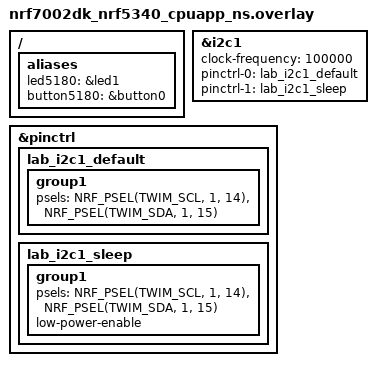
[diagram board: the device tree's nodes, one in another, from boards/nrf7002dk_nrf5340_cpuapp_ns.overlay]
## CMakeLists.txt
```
# SPDX-License-Identifier: Apache-2.0

cmake_minimum_required(VERSION 3.20.0)
find_package(Zephyr REQUIRED HINTS $ENV{ZEPHYR_BASE})
project(lab0_sum)

target_sources(app PRIVATE src/main.c)

if(CONFIG_SUM_PRINT)
    target_sources(app PRIVATE sum_printk/sum_printk.c)
    target_include_directories(app PRIVATE sum_printk)
elseif(CONFIG_SUM_LOG)
    target_sources(app PRIVATE sum_log/sum_log.c)
    target_include_directories(app PRIVATE sum_log)
endif()
```

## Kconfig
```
mainmenu "Lab 0 application"

source "Kconfig.zephyr"

choice SUM_IMPLEMENTATION
    prompt "Sum implementation"
    default SUM_PRINT

config SUM_PRINT
    bool "Use printk"

config SUM_LOG
    bool "Use Logger"
    depends on LOG

endchoice
```

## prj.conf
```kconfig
CONFIG_GPIO=y
CONFIG_SERIAL=y
CONFIG_CONSOLE=y
CONFIG_UART_CONSOLE=y
CONFIG_PRINTK=y

CONFIG_LOG=y
CONFIG_LOG_BACKEND_UART=y
CONFIG_LOG_DEFAULT_LEVEL=3

CONFIG_SUM_LOG=y

CONFIG_I2C=y
CONFIG_TFM_SECURE_UART=n
CONFIG_TFM_LOG_LEVEL_SILENCE=y

CONFIG_SENSOR=y
CONFIG_CBPRINTF_FP_SUPPORT=y
```

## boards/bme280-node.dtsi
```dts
bme5180: bme280@77 {
    compatible = "i2c-device";
    status = "okay";
    reg = <0x77>;
};
```

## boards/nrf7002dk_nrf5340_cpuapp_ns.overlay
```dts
#include <zephyr/dt-bindings/pinctrl/nrf-pinctrl.h>

/ {
    aliases {
        led5180 = &led1;
        button5180 = &button0;
    };
};

&i2c1 {
    status = "okay";
    clock-frequency = <100000>;

    pinctrl-0 = <&lab_i2c1_default>;
    pinctrl-1 = <&lab_i2c1_sleep>;
    pinctrl-names = "default", "sleep";

    #include "bme280-node.dtsi"
};

&pinctrl {
    lab_i2c1_default: lab_i2c1_default {
        group1 {
            psels = <NRF_PSEL(TWIM_SCL, 1, 14)>,
                    <NRF_PSEL(TWIM_SDA, 1, 15)>;
        };
    };

    lab_i2c1_sleep: lab_i2c1_sleep {
        group1 {
            psels = <NRF_PSEL(TWIM_SCL, 1, 14)>,
                    <NRF_PSEL(TWIM_SDA, 1, 15)>;
            low-power-enable;
        };
    };
};
```

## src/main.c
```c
#include <zephyr/kernel.h>
#include <zephyr/drivers/i2c.h>
#include <zephyr/sys/byteorder.h>
#include <zephyr/sys/printk.h>
#include <errno.h>
#include "bme_temperature.h"

static const struct i2c_dt_spec bme =
    I2C_DT_SPEC_GET(DT_NODELABEL(bme5180));

static uint16_t dig_T1;
static int16_t dig_T2;
static int16_t dig_T3;

static int wait_ready(void)
{
    for (int i = 0; i < 50; i++) {
        uint8_t status;
        int ret = i2c_reg_read_byte_dt(&bme, 0xF3, &status);

        if (ret < 0) {
            return ret;
        }

        if ((status & 0x09) == 0) {
            return 0;
        }

        k_msleep(2);
    }

    return -ETIMEDOUT;
}

static double compensate_temperature(int32_t raw)
{
    return bme_compensate_temperature(raw, dig_T1, dig_T2, dig_T3);
}

int main(void)
{
    int ret;
    uint8_t chip_id;
    uint8_t calibration[6];

    if (!i2c_is_ready_dt(&bme)) {
        printk("I2C controller not ready\n");
        return 0;
    }

    k_msleep(10);

    ret = i2c_reg_read_byte_dt(&bme, 0xD0, &chip_id);
    if (ret < 0) {
        printk("Chip ID read failed: %d\n", ret);
        return 0;
    }

    if (chip_id != 0x60) {
        printk("Unexpected chip ID: 0x%02x\n",
               (unsigned int)chip_id);
        return 0;
    }

    printk("BME280 connected!\n");

    ret = i2c_reg_write_byte_dt(&bme, 0xE0, 0xB6);
    if (ret < 0) {
        printk("Sensor reset failed: %d\n", ret);
        return 0;
    }

    k_msleep(10);

    ret = wait_ready();
    if (ret < 0) {
        printk("Sensor startup failed: %d\n", ret);
        return 0;
    }

    ret = i2c_burst_read_dt(&bme, 0x88,
                           calibration, sizeof(calibration));
    if (ret < 0) {
        printk("Calibration read failed: %d\n", ret);
        return 0;
    }

    dig_T1 = sys_get_le16(&calibration[0]);
    dig_T2 = (int16_t)sys_get_le16(&calibration[2]);
    dig_T3 = (int16_t)sys_get_le16(&calibration[4]);

    printk("Calibration: T1=%u, T2=%d, T3=%d\n",
           (unsigned int)dig_T1, (int)dig_T2, (int)dig_T3);

    while (1) {
        ret = i2c_reg_write_byte_dt(&bme, 0xF4, 0x21);
        if (ret < 0) {
            printk("Measurement start failed: %d\n", ret);
            k_msleep(2000);
            continue;
        }

        k_msleep(10);

        ret = wait_ready();
        if (ret < 0) {
            printk("Measurement wait failed: %d\n", ret);
            k_msleep(2000);
            continue;
        }

        uint8_t data[3];

        ret = i2c_burst_read_dt(&bme, 0xFA, data, sizeof(data));
        if (ret < 0) {
            printk("Temperature read failed: %d\n", ret);
            k_msleep(2000);
            continue;
        }

        int32_t raw = bme_decode_raw(data);
        
        if (raw == 0x80000) {
            printk("Temperature sample unavailable\n");
            k_msleep(2000);
            continue;
        }

        double temperature = compensate_temperature(raw);

        printk("Raw: %ld | Temperature: %.2f C\n",
               (long)raw, temperature);

        k_msleep(2000);
    }

    return 0;
}
```

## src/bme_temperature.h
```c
#ifndef BME_TEMPERATURE_H
#define BME_TEMPERATURE_H

#include <stdint.h>

static inline int32_t bme_decode_raw(const uint8_t data[3])
{
    return ((int32_t)data[0] << 12) | ((int32_t)data[1] << 4) | (data[2] >> 4);
}

static inline double bme_compensate_temperature(
    int32_t raw, uint16_t t1, int16_t t2, int16_t t3)
{
    double var1 = (raw / 16384.0 - t1 / 1024.0) * t2;
    double difference = raw / 131072.0 - t1 / 8192.0;
    double var2 = difference * difference * t3;

    return (var1 + var2) / 5120.0;
}

#endif
```
